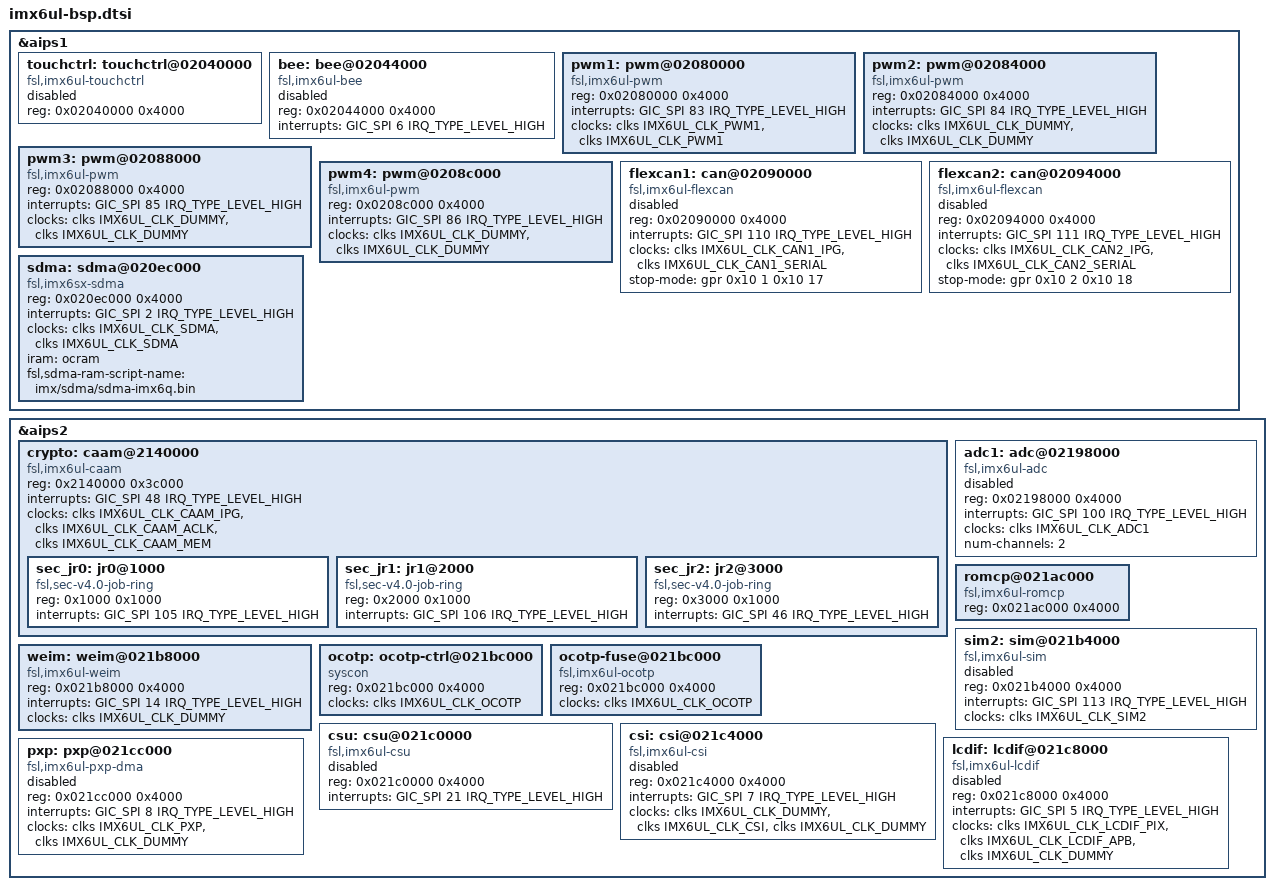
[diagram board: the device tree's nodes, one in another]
/*
 * Copyright 2015 Freescale Semiconductor, Inc.
 *
 * This program is free software; you can redistribute it and/or modify
 * it under the terms of the GNU General Public License version 2 as
 * published by the Free Software Foundation.
 */

&aips1 {
	/* FIXME: already defined in imx6ul.dtsi
	sai1: sai@02028000 {
		compatible = "fsl,imx6ul-sai";
		reg = <0x02028000 0x4000>;
		interrupts = <GIC_SPI 97 IRQ_TYPE_LEVEL_HIGH>;
		clocks = <&clks IMX6UL_CLK_SAI1_IPG>,
			 <&clks IMX6UL_CLK_SAI1>,
			 <&clks 0>, <&clks 0>;
		clock-names = "bus", "mclk1", "mclk2", "mclk3";
		dma-names = "rx", "tx";
		dmas = <&sdma 35 25 0>, <&sdma 36 25 0>;
		status = "disabled";
	};
	*/

	/* FIXME: already defined in imx6ul.dtsi
	sai2: sai@0202c000 {
		compatible = "fsl,imx6ul-sai";
		reg = <0x0202c000 0x4000>;
		interrupts = <GIC_SPI 98 IRQ_TYPE_LEVEL_HIGH>;
		clocks = <&clks IMX6UL_CLK_SAI2_IPG>,
			 <&clks IMX6UL_CLK_SAI2>,
			 <&clks 0>, <&clks 0>;
		clock-names = "bus", "mclk1", "mclk2", "mclk3";
		dma-names = "rx", "tx";
		dmas = <&sdma 37 25 0>, <&sdma 38 25 0>;
		status = "disabled";
	};
	*/

	/* FIXME: already defined in imx6ul.dtsi
	sai3: sai@02030000 {
		compatible = "fsl,imx6ul-sai";
		reg = <0x02030000 0x4000>;
		interrupts = <GIC_SPI 24 IRQ_TYPE_LEVEL_HIGH>;
		clocks = <&clks IMX6UL_CLK_DUMMY>,
			 <&clks IMX6UL_CLK_DUMMY>,
			 <&clks 0>, <&clks 0>;
		clock-names = "bus", "mclk1", "mclk2", "mclk3";
		status = "disabled";
	};
	*/


	touchctrl: touchctrl@02040000 {
		compatible = "fsl,imx6ul-touchctrl";
		reg = <0x02040000 0x4000>;
		status = "disabled";
	};

	bee: bee@02044000 {
		compatible = "fsl,imx6ul-bee";
		reg = <0x02044000 0x4000>;
		interrupts = <GIC_SPI 6 IRQ_TYPE_LEVEL_HIGH>;
		status = "disabled";
	};

	pwm1: pwm@02080000 {
		compatible = "fsl,imx6ul-pwm", "fsl,imx27-pwm";
		reg = <0x02080000 0x4000>;
		interrupts = <GIC_SPI 83 IRQ_TYPE_LEVEL_HIGH>;
		clocks = <&clks IMX6UL_CLK_PWM1>,
			 <&clks IMX6UL_CLK_PWM1>;
		clock-names = "ipg", "per";
		#pwm-cells = <2>;
	};

	pwm2: pwm@02084000 {
		compatible = "fsl,imx6ul-pwm", "fsl,imx27-pwm";
		reg = <0x02084000 0x4000>;
		interrupts = <GIC_SPI 84 IRQ_TYPE_LEVEL_HIGH>;
		clocks = <&clks IMX6UL_CLK_DUMMY>,
			 <&clks IMX6UL_CLK_DUMMY>;
		clock-names = "ipg", "per";
		#pwm-cells = <2>;
	};

	pwm3: pwm@02088000 {
		compatible = "fsl,imx6ul-pwm", "fsl,imx27-pwm";
		reg = <0x02088000 0x4000>;
		interrupts = <GIC_SPI 85 IRQ_TYPE_LEVEL_HIGH>;
		clocks = <&clks IMX6UL_CLK_DUMMY>,
			 <&clks IMX6UL_CLK_DUMMY>;
		clock-names = "ipg", "per";
		#pwm-cells = <2>;
	};

	pwm4: pwm@0208c000 {
		compatible = "fsl,imx6ul-pwm", "fsl,imx27-pwm";
		reg = <0x0208c000 0x4000>;
		interrupts = <GIC_SPI 86 IRQ_TYPE_LEVEL_HIGH>;
		clocks = <&clks IMX6UL_CLK_DUMMY>,
			 <&clks IMX6UL_CLK_DUMMY>;
		clock-names = "ipg", "per";
		#pwm-cells = <2>;
	};

	flexcan1: can@02090000 {
		compatible = "fsl,imx6ul-flexcan", "fsl,imx6q-flexcan";
		reg = <0x02090000 0x4000>;
		interrupts = <GIC_SPI 110 IRQ_TYPE_LEVEL_HIGH>;
		clocks = <&clks IMX6UL_CLK_CAN1_IPG>,
			 <&clks IMX6UL_CLK_CAN1_SERIAL>;
		clock-names = "ipg", "per";
		stop-mode = <&gpr 0x10 1 0x10 17>;
		status = "disabled";
	};

	flexcan2: can@02094000 {
		compatible = "fsl,imx6ul-flexcan", "fsl,imx6q-flexcan";
		reg = <0x02094000 0x4000>;
		interrupts = <GIC_SPI 111 IRQ_TYPE_LEVEL_HIGH>;
		clocks = <&clks IMX6UL_CLK_CAN2_IPG>,
			 <&clks IMX6UL_CLK_CAN2_SERIAL>;
		clock-names = "ipg", "per";
		stop-mode = <&gpr 0x10 2 0x10 18>;
		status = "disabled";
	};

	sdma: sdma@020ec000 {
		compatible = "fsl,imx6sx-sdma", "fsl,imx35-sdma";
		reg = <0x020ec000 0x4000>;
		interrupts = <GIC_SPI 2 IRQ_TYPE_LEVEL_HIGH>;
		clocks = <&clks IMX6UL_CLK_SDMA>,
			 <&clks IMX6UL_CLK_SDMA>;
		clock-names = "ipg", "ahb";
		#dma-cells = <3>;
		iram = <&ocram>;
		fsl,sdma-ram-script-name = "imx/sdma/sdma-imx6q.bin";
	};
};

&aips2 {
	crypto: caam@2140000 {
		compatible = "fsl,imx6ul-caam", "fsl,sec-v4.0";
		#address-cells = <1>;
		#size-cells = <1>;
		reg = <0x2140000 0x3c000>;
		ranges = <0 0x2140000 0x3c000>;
		interrupts = <GIC_SPI 48 IRQ_TYPE_LEVEL_HIGH>;
		clocks = <&clks IMX6UL_CLK_CAAM_IPG>, <&clks IMX6UL_CLK_CAAM_ACLK>,
			<&clks IMX6UL_CLK_CAAM_MEM>;
		clock-names = "caam_ipg", "caam_aclk", "caam_mem";

		sec_jr0: jr0@1000 {
			compatible = "fsl,sec-v4.0-job-ring";
			reg = <0x1000 0x1000>;
			interrupts = <GIC_SPI 105 IRQ_TYPE_LEVEL_HIGH>;
		};

		sec_jr1: jr1@2000 {
			compatible = "fsl,sec-v4.0-job-ring";
			reg = <0x2000 0x1000>;
			interrupts = <GIC_SPI 106 IRQ_TYPE_LEVEL_HIGH>;
		};
		sec_jr2: jr2@3000 {
			compatible = "fsl,sec-v4.0-job-ring";
			reg = <0x3000 0x1000>;
			interrupts = <GIC_SPI 46 IRQ_TYPE_LEVEL_HIGH>;
		};
	};

	adc1: adc@02198000 {
		compatible = "fsl,imx6ul-adc", "fsl,vf610-adc";
		reg = <0x02198000 0x4000>;
		interrupts = <GIC_SPI 100 IRQ_TYPE_LEVEL_HIGH>;
		clocks = <&clks IMX6UL_CLK_ADC1>;
		num-channels = <2>;
		clock-names = "adc";
		status = "disabled";
	};

	romcp@021ac000 {
		compatible = "fsl,imx6ul-romcp", "syscon";
		reg = <0x021ac000 0x4000>;
	};

	sim2: sim@021b4000 {
		compatible = "fsl,imx6ul-sim";
		reg = <0x021b4000 0x4000>;
		interrupts = <GIC_SPI 113 IRQ_TYPE_LEVEL_HIGH>;
		clocks = <&clks IMX6UL_CLK_SIM2>;
		clock-names = "sim";
		status = "disabled";
	};

	weim: weim@021b8000 {
		compatible = "fsl,imx6ul-weim", "fsl,imx6q-weim";
		reg = <0x021b8000 0x4000>;
		interrupts = <GIC_SPI 14 IRQ_TYPE_LEVEL_HIGH>;
		clocks = <&clks IMX6UL_CLK_DUMMY>;
	};

	ocotp: ocotp-ctrl@021bc000 {
		compatible = "syscon";
		reg = <0x021bc000 0x4000>;
		clocks = <&clks IMX6UL_CLK_OCOTP>;
	};

	ocotp-fuse@021bc000 {
		compatible = "fsl,imx6ul-ocotp", "fsl,imx6q-ocotp";
		reg = <0x021bc000 0x4000>;
		clocks = <&clks IMX6UL_CLK_OCOTP>;
	};

	csu: csu@021c0000 {
		compatible = "fsl,imx6ul-csu";
		reg = <0x021c0000 0x4000>;
		interrupts = <GIC_SPI 21 IRQ_TYPE_LEVEL_HIGH>;
		status = "disabled";
	};

	csi: csi@021c4000 {
		compatible = "fsl,imx6ul-csi", "fsl,imx6s-csi";
		reg = <0x021c4000 0x4000>;
		interrupts = <GIC_SPI 7 IRQ_TYPE_LEVEL_HIGH>;
		clocks = <&clks IMX6UL_CLK_DUMMY>,
			<&clks IMX6UL_CLK_CSI>,
			<&clks IMX6UL_CLK_DUMMY>;
		clock-names = "disp-axi", "csi_mclk", "disp_dcic";
		status = "disabled";
	};

	lcdif: lcdif@021c8000 {
		compatible = "fsl,imx6ul-lcdif", "fsl,imx28-lcdif";
		reg = <0x021c8000 0x4000>;
		interrupts = <GIC_SPI 5 IRQ_TYPE_LEVEL_HIGH>;
		clocks = <&clks IMX6UL_CLK_LCDIF_PIX>,
			 <&clks IMX6UL_CLK_LCDIF_APB>,
			 <&clks IMX6UL_CLK_DUMMY>;
		clock-names = "pix", "axi", "disp_axi";
		status = "disabled";
	};

	pxp: pxp@021cc000 {
		compatible = "fsl,imx6ul-pxp-dma", "fsl,imx6sl-pxp-dma", "fsl,imx6dl-pxp-dma";
		reg = <0x021cc000 0x4000>;
		interrupts = <GIC_SPI 8 IRQ_TYPE_LEVEL_HIGH>;
		clocks = <&clks IMX6UL_CLK_PXP>,
			 <&clks IMX6UL_CLK_DUMMY>;
		clock-names = "pxp-axi", "disp-axi";
		status = "disabled";
	};

	/* FIXME: already defined in imx6ul.dtsi
	dma_apbh: dma-apbh@01804000 {
		compatible = "fsl,imx6ul-dma-apbh", "fsl,imx28-dma-apbh";
		reg = <0x01804000 0x2000>;
		interrupts = <GIC_SPI 13 IRQ_TYPE_LEVEL_HIGH>,
			     <GIC_SPI 13 IRQ_TYPE_LEVEL_HIGH>,
			     <GIC_SPI 13 IRQ_TYPE_LEVEL_HIGH>,
			     <GIC_SPI 13 IRQ_TYPE_LEVEL_HIGH>;
		interrupt-names = "gpmi0", "gpmi1", "gpmi2", "gpmi3";
		#dma-cells = <1>;
		dma-channels = <4>;
		clocks = <&clks IMX6UL_CLK_APBHDMA>;
	};
	*/

	/* FIXME: already defined in imx6ul.dtsi
	gpmi: gpmi-nand@01806000{
		compatible = "fsl,imx6sx-gpmi-nand";
		#address-cells = <1>;
		#size-cells = <1>;
		reg = <0x01806000 0x2000>, <0x01808000 0x4000>;
		reg-names = "gpmi-nand", "bch";
		interrupts = <GIC_SPI 15 IRQ_TYPE_LEVEL_HIGH>;
		interrupt-names = "bch";
		clocks = <&clks IMX6UL_CLK_GPMI_IO>,
			 <&clks IMX6UL_CLK_GPMI_APB>,
			 <&clks IMX6UL_CLK_GPMI_BCH>,
			 <&clks IMX6UL_CLK_GPMI_BCH_APB>,
			 <&clks IMX6UL_CLK_PER_BCH>;
		clock-names = "gpmi_io", "gpmi_apb", "gpmi_bch",
			      "gpmi_bch_apb", "per1_bch";
		dmas = <&dma_apbh 0>;
		dma-names = "rx-tx";
		status = "disabled";
	};
	*/
};
